# max32660 register map
Vendor: Maxim Integrated; Series: ARMCM4; File version: 1.0
CPU: CM4 r2p1, little endian, MPU, FPU, 3 interrupt priority bits
Registers are 32-bit, read-write, reset 0x0 unless marked. A register's access mark holds for its fields unless they carry their own. Offsets are from the block's base; [hi:lo] are bit positions; {n}, {i} and the like mark numbered series; 'fields as' and 'values as' point back to an identical list.

## GCR — Global Control Registers.
Base 0x40000000
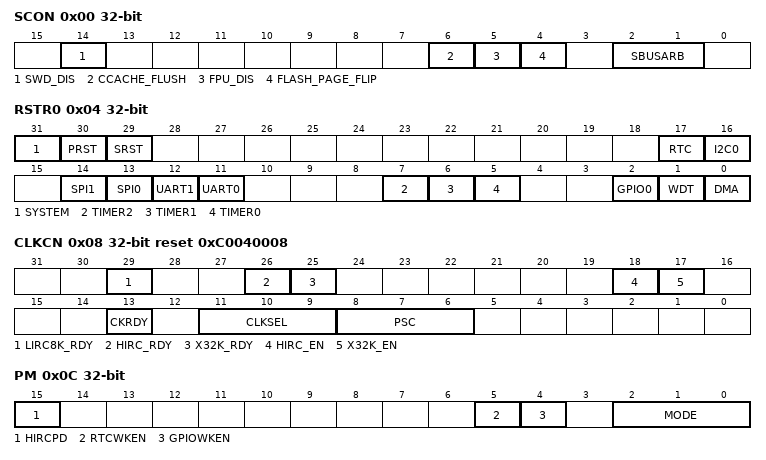
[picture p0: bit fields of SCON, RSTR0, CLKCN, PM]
0x00 SCON — System Control.
  [14] SWD_DIS — Serial Wire Debug Disable
    0=Enable JTAG SWD; 1=Disable JTAG SWD
  [6] CCACHE_FLUSH — Code Cache Flush. This bit is used to flush the code caches and the instruction buffer of the Cortex-M4.
    0=Normal Code Cache Operation; 1=flush (Code Caches and CPU instruction buffer are flushed)
  [5] FPU_DIS — Floating Point Unit Disable
    0=enable Floating point unit; 1=disable floating point unit
  [4] FLASH_PAGE_FLIP — Flips the Flash bottom and top halves. (Depending on the total flash size, each half is either 256K or 512K). Initiating a flash page flip will cause a flush of both the data buffer on the DCODE bus and the internal instruction buffer.
    0=normal (Physical layout matches logical layout.); 1=swapped (Bottom half mapped to logical top half and vice versa.)
  [2:1] SBUSARB — System bus abritration scheme. These bits are used to select between Fixed-burst abritration and Round-Robin scheme. The Round-Robin scheme is selected by default. These bits are reset by the system reset.
    0=fix (Fixed Burst abritration.); 1=Round-robin scheme
0x04 RSTR0 — Reset.
  [all] fields
    on write: 1=reset (Starts reset operation.) | on read: 0=Reset_Done (Reset Complete); 1=Busy (Reset Busy)
  [31] SYSTEM — System Reset. Setting this bit to 1 resets the CPU core and all peripherals, including the watchdog timer.
  [30] PRST — Peripheral Reset. Setting this bit to 1 resets all peripherals. The CPU core, the watchdog timer, and all GPIO pins are unaffected by this reset.
  [29] SRST — Soft Reset.Write 1 to perform a Soft Reset. A soft reset performs a Peripheral Reset and also resets the GPIO peripheral but does not reset the CPU or Watchdog Timer.
  [17] RTC — Real Time Clock Reset.
  [16] I2C0 — I2C0 Reset.
  [14] SPI1 — SPI1 Reset. Setting this bit to 1 resets all SPI 1 blocks.
  [13] SPI0 — SPI0 Reset. Setting this bit to 1 resets all SPI 0 blocks.
  [12] UART1 — UART1 Reset. Setting this bit to 1 resets all UART 1 blocks.
  [11] UART0 — UART0 Reset. Setting this bit to 1 resets all UART 0 blocks.
  [7] TIMER2 — Timer2 Reset. Setting this bit to 1 resets Timer 2 blocks.
  [6] TIMER1 — Timer1 Reset. Setting this bit to 1 resets Timer 1 blocks.
  [5] TIMER0 — Timer0 Reset. Setting this bit to 1 resets Timer 0 blocks.
  [2] GPIO0 — GPIO0 Reset. Setting this bit to 1 resets GPIO0 pins to their default states.
  [1] WDT — Watchdog Timer Reset.
  [0] DMA — DMA Reset.
0x08 CLKCN reset 0xC0040008 — Clock Control.
  [29] LIRC8K_RDY — 8kHz Low Frequency Reference Clock Ready.
    0=not (Not Ready); 1=ready (Clock Ready)
  [26] HIRC_RDY — 60MHz HIRC Ready.
    0=not (Not Ready); 1=ready (HIRC Ready)
  [25] X32K_RDY ro — 32kHz Crystal Oscillator Ready
    0=not (Not Ready); 1=Ready (X32K Ready)
  [18] HIRC_EN — 60MHz High Frequency Internal Reference Clock Enable.
    0=dis (Is Disabled.); 1=en (Is Enabled.)
  [17] X32K_EN — 32kHz Crystal Oscillator Enable.
    0=dis (Is Disabled.); 1=en (Is Enabled.)
  [13] CKRDY ro — Clock Ready. This read only bit reflects whether the currently selected system clock source is running.
    0=busy (Switchover to the new clock source (as selected by CLKSEL) has not yet occurred.); 1=ready (System clock running from CLKSEL clock source.)
  [11:9] CLKSEL — Clock Source Select. This 3 bit field selects the source for the system clock.
    0=HIRC (The internal 96 MHz oscillator is used for the system clock.); 3=nanoRing (The nano-ring output is used for the system clock.); 6=HFXIN is used for the system clock
  [8:6] PSC — Prescaler Select. This 3 bit field sets the system operating frequency by controlling the prescaler that divides the output of the PLL0.
    0=div1 (Divide by 1.); 1=div2 (Divide by 2.); 2=div4 (Divide by 4.); 3=div8 (Divide by 8.); 4=div16 (Divide by 16.); 5=div32 (Divide by 32.); 6=div64 (Divide by 64.); 7=div128 (Divide by 128.)
0x0C PM — Power Management.
  [15] HIRCPD — HIRC Power Down. This bit selects HIRC power state in DEEPSLEEP mode.
    0=active (Mode is Active.); 1=deepsleep (Powered down in DEEPSLEEP.)
  [5] RTCWKEN — RTC Alarm Wake Up Enable. This bit enables RTC alarm as wakeup source. If enabled, the desired RTC alarm must be configured via the RTC control registers.
    0=dis (Wake Up Disable.); 1=en (Wake Up Enable.)
  [4] GPIOWKEN — GPIO Wake Up Enable. This bit enables all GPIO pins as potential wakeup sources. Any GPIO configured for wakeup is capable of causing an exit from IDLE or STANDBY modes when this bit is set.
    0=dis (Wake Up Disable.); 1=en (Wake Up Enable.)
  [2:0] MODE — Operating Mode. This two bit field selects the current operating mode for the device. Note that code execution only occurs during ACTIVE mode.
    0=Active Mode; 3=Shutdown Mode; 4=Backup Mode
0x18 PCKDIV reset 0x1 — Peripheral Clock Divider.
  [1:0] AONCD — Always-ON(AON) domain CLock Divider. These bits define the AON domain clock divider.
    0=div_4 (PCLK divide by 4.); 1=div_8 (PCLK divide by 8.); 2=div_16 (PCLK divide by 16.); 3=div_32 (PCLK divide by 32.)
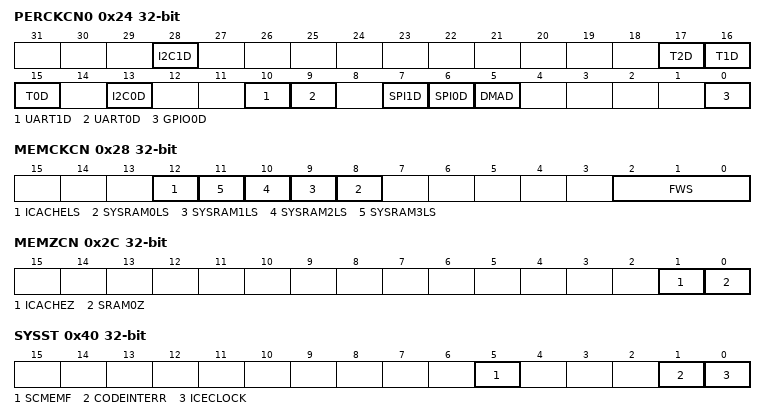
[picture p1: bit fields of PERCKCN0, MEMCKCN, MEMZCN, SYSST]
0x24 PERCKCN0 — Peripheral Clock Disable.
  [all] fields
    0=en (enable it.); 1=dis (disable it.)
  [28] I2C1D — I2C 1 Disable.
  [17] T2D — Timer 2 Disable.
  [16] T1D — Timer 1 Disable.
  [15] T0D — Timer 0 Disable.
  [13] I2C0D — I2C 0 Disable.
  [10] UART1D — UART 1 Disable.
  [9] UART0D — UART 0 Disable.
  [7] SPI1D — SPI 1 Disable.
  [6] SPI0D — SPI 0 Disable.
  [5] DMAD — DMA Disable.
  [0] GPIO0D — GPIO0 Disable.
0x28 MEMCKCN — Memory Clock Control Register.
  [12] ICACHELS — ICache RAM Light Sleep Mode.
    0=active (Memory is active.); 1=light_sleep (Memory is in Light Sleep mode.)
  [n+8] SYSRAM{n}LS (n=0..3) — System RAM {n} Light Sleep Mode.
    values as ICACHELS
  [2:0] FWS — Flash Wait State. These bits define the number of wait-state cycles per Flash data read access. Minimum wait state is 2.
0x2C MEMZCN — Memory Zeroize Control.
  [1] ICACHEZ — Instruction Cache.
    0=nop (No operation/complete.); 1=Start operation
  [0] SRAM0Z — System RAM Block 0.
    0=nop (No operation/complete.); 1=Start operation
0x34 SCCK reset 0x1414 — Smart Card Clock Control.
0x38 MPRI0 reset 0x1414 — Master Priority Control Register 0.
0x3C MPRI1 reset 0x1414 — Mater Priority Control Register 1.
0x40 SYSST — System Status Register.
  [5] SCMEMF — System Cache Memory Fault Flag. This bit indicates a memory fault has occured in the System Cache while receiving data from the Hyperbus Interface.
    0=Normal Operating Condition; 1=Memory Fault
  [1] CODEINTERR — Code Integrity Error Flag. This bit indicates a code integrity error has occured in XiP interface.
    0=Normal Operating Condition; 1=Code Integrity Error
  [0] ICECLOCK — ARM ICE Lock Status.
    0=unlocked (ICE is unlocked.); 1=locked (ICE is locked.)
0x44 RSTR1 — Reset 1.
  [0] I2C1 — I2C1 Reset.
    on write: 1=reset (Starts reset operation.) | on read: 0=reset_done (Reset complete.); 1=busy (Reset in progress.)
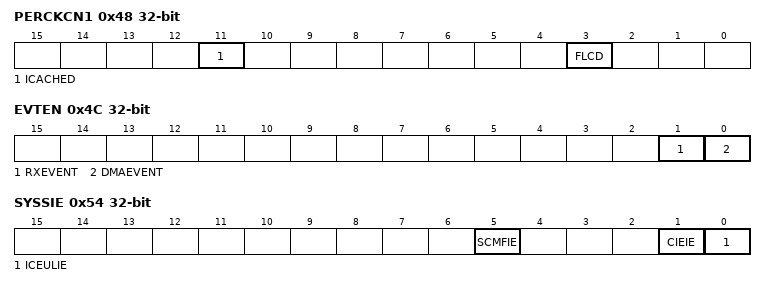
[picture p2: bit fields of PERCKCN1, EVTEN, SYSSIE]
0x48 PERCKCN1 — Peripheral Clock Disable.
  [11] ICACHED — ICache Clock Disable.
    0=en (Enable.); 1=dis (Disable.)
  [3] FLCD — Secure Flash Controller Disable.
    0=en (Enable.); 1=dis (Disable.)
0x4C EVTEN — Event Enable Register.
  [1] RXEVENT — Enable RXEV pin event. When this bit is set, a logic high of GPIO0[24] will cause an RXEV event to wake the CPU from WFE sleep mode.
  [0] DMAEVENT — Enable DMA event. When this bit is set, a DMA event will cause an RXEV event to wake the CPU from WFE sleep mode.
0x50 REVISION ro
  [15:0] REVISION — Manufacturer Chip Revision.
0x54 SYSSIE — System Status Interrupt Enable Register.
  [all] fields
    0=dis (disabled.); 1=en (enabled.)
  [5] SCMFIE — System Cache Memory Fault Interrupt Enable.
  [1] CIEIE — Code Integrity Error Interrupt Enable.
  [0] ICEULIE — ARM ICE Unlock Interrupt Enable.
